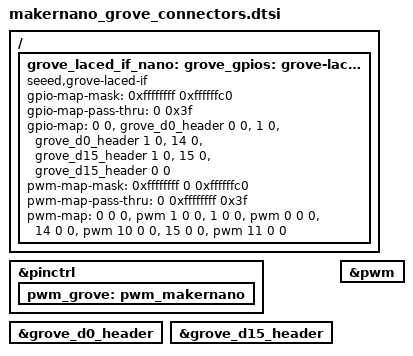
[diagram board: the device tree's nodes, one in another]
/*
 * Copyright (c) 2023-2024 TiaC Systems
 * SPDX-License-Identifier: Apache-2.0
 */

#include <bridle/dt-bindings/seeed_grove_pwms_defaults.h>

&pinctrl {
	pwm_grove: pwm_makernano {};
};

#include "grove_d0_connector.dtsi"
#include "grove_d15_connector.dtsi"

grove_uart_header: &grove_d0_header {};
grove_i2c_header: &grove_d15_header {};

/* tweaked labels: Pin 0 isn't the primary data line! */
grove_d1_header: &grove_d0_header {};	/* D0 is on D1 header pin 1 */
grove_d14_header: &grove_d15_header {};	/* D14 is on D27 header pin 1 */

/ {
	grove_laced_if_nano: grove-laced-if-nano {
		compatible = "seeed,grove-laced-if";

		#gpio-cells = <2>;
		gpio-map-mask = <0xffffffff 0xffffffc0>;
		gpio-map-pass-thru = <0 0x3f>;
		gpio-map =
			<0 0 &grove_d0_header 0 0>,	/* GP1: UART0-RX as GPIO */
			<1 0 &grove_d0_header 1 0>,	/* GP0: UART0-TX as GPIO */
			/*  2 - GP2:  not wired */
			/*  3 - GP3:  not wired */
			/*  4 - GP4:  not wired */
			/*  5 - GP5:  not wired */
			/*  6 - GP6:  not wired */
			/*  7 - GP7:  not wired */
			/*  8 - GP8:  not wired */
			/*  9 - GP9:  not wired */
			/* 10 - GP17: not wired */
			/* 11 - GP19: not wired */
			/* 12 - GP16: not wired */
			/* 13 - GP18: not wired */
			<14 0 &grove_d15_header 1 0>,	/* GP26: A0 / I2C1-SDA as GPIO */
			<15 0 &grove_d15_header 0 0>;	/* GP27: A1 / I2C1-SCL as GPIO */
			/* 16 - GP28: A2 as GPIO not wired */
			/* 17 - GP29: A3 as GPIO not wired */
			/* 18 - GP12: not wired */
			/* 19 - GP13: not wired */
			/* 20 - GP14: not wired */
			/* 21 - GP15: not wired */
			/* 22 - not possible */
			/* 23 - not possible */
			/* 24 - not possible */
			/* 25 - not possible */
			/* 26 - not possible */
			/* 27 - not possible */
			/* 28 - not possible */
			/* 29 - not possible */
			/* 30 - not possible */
			/* 31 - not possible */

		#pwm-cells = <3>;
		pwm-map-mask = <0xffffffff 0 0xffffffc0>;
		pwm-map-pass-thru = <0 0xffffffff 0x3f>;
		pwm-map =
			<0 0 0 &pwm 1 0 0>,	/* GP1: PWM0CHB (1) */
			<1 0 0 &pwm 0 0 0>,	/* GP0: PWM0CHA (0) */
			/*  2 - GP2:  PWM1CHA (2)  not wired */
			/*  3 - GP3:  PWM1CHB (3)  not wired */
			/*  4 - GP4:  PWM2CHA (4)  not wired */
			/*  5 - GP5:  PWM2CHB (5)  not wired */
			/*  6 - GP6:  PWM3CHA (6)  not wired */
			/*  7 - GP7:  PWM3CHB (7)  not wired */
			/*  8 - GP8:  PWM4CHA (8)  not wired */
			/*  9 - GP9:  PWM4CHB (9)  not wired */
			/* 10 - GP17: PWM0CHB (1)  not wired */
			/* 11 - GP19: PWM1CHB (3)  not wired */
			/* 12 - GP16: PWM0CHA (0)  not wired */
			/* 13 - GP18: PWM1CHA (2)  not wired */
			<14 0 0 &pwm 10 0 0>,	/* GP26: A0 as PWM5CHA (10) */
			<15 0 0 &pwm 11 0 0>;	/* GP27: A1 as PWM5CHB (11) */
			/* 16 - GP28: A2 as PWM6CHA (12) not wired */
			/* 17 - GP29: A3 as PWM6CHB (13) not wired */
			/* 18 - GP12: PWM6CHA (12) not wired */
			/* 19 - GP13: PWM6CHB (13) not wired */
			/* 20 - GP14: PWM7CHA (14) not wired */
			/* 21 - GP15: PWM7CHB (15) not wired */
			/* 22 - not possible */
			/* 23 - not possible */
			/* 24 - not possible */
			/* 25 - not possible */
			/* 26 - not possible */
			/* 27 - not possible */
			/* 28 - not possible */
			/* 29 - not possible */
			/* 30 - not possible */
			/* 31 - not possible */
	};
};

grove_gpios: &grove_laced_if_nano {};
grove_pwms: &grove_laced_if_nano {};

grove_pwm_d0: &pwm {};
grove_pwm_d1: &pwm {};
grove_pwm_d14: &pwm {};
grove_pwm_d15: &pwm {};
